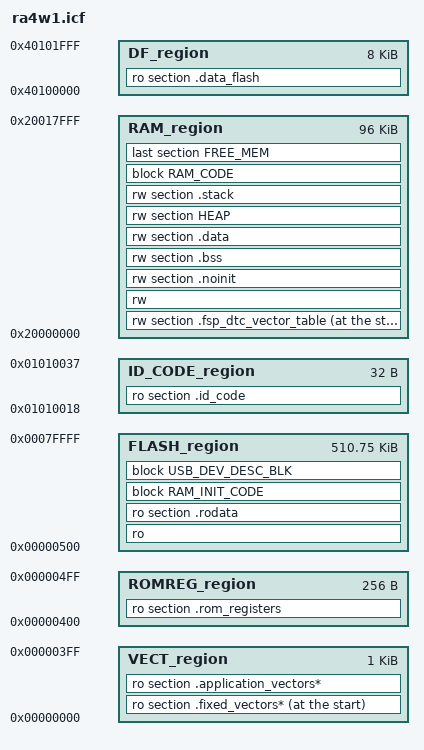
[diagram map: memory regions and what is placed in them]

/*-Memory Regions-*/
define symbol region_VECT_start    = 0x00000000;
define symbol region_VECT_end      = 0x000003FF;
define symbol region_ROMREG_start  = 0x00000400;
define symbol region_ROMREG_end    = 0x000004FF;
define symbol region_FLASH_start   = 0x00000500;
define symbol region_FLASH_end     = 0x0007FFFF;
define symbol region_RAM_start     = 0x20000000;
define symbol region_RAM_end       = 0x20017FFF;
define symbol region_DF_start      = 0x40100000;
define symbol region_DF_end        = 0x40101FFF;

define symbol region_ID_CODES_start    = 0x01010018;
define symbol region_ID_CODES_end      = 0x01010037;

/* Stack and heap sizes are defined in bsp_cfg.h */

define memory mem with size     = 4G;
define region VECT_region       = mem:[from region_VECT_start   to region_VECT_end];
define region ROMREG_region     = mem:[from region_ROMREG_start to region_ROMREG_end];
define region FLASH_region      = mem:[from region_FLASH_start  to region_FLASH_end];
define region RAM_region        = mem:[from region_RAM_start    to region_RAM_end];
define region DF_region         = mem:[from region_DF_start     to region_DF_end];

define region ID_CODE_region    = mem:[from region_ID_CODES_start   to region_ID_CODES_end];

initialize manually { readwrite };
do not initialize   { zeroinit };
initialize manually { section .code_in_ram };
/* Main thread local storage */
initialize manually { section __DLIB_PERTHREAD };

define block RAM_INIT_CODE   { section .code_in_ram_init };
define block RAM_CODE        { section .code_in_ram };
keep                         { section .vector*};

define block USB_DEV_DESC_BLK with fixed order, alignment = 1
                                           { ro data section .usb_device_desc_fs,
                                             ro data section .usb_config_desc_fs,
                                             ro data section .usb_interface_desc_fs,
                                             ro data section .usb_device_desc_hs,
                                             ro data section .usb_config_desc_hs,
                                             ro data section .usb_interface_desc_hs };
keep                                       { section .usb_*};

place at start of VECT_region  { ro section .fixed_vectors* };
place in VECT_region           { ro section .application_vectors* };
place in ROMREG_region         { ro section .rom_registers };
place in FLASH_region   { ro,
                          ro section .rodata,
                          block RAM_INIT_CODE,
                          block USB_DEV_DESC_BLK };
/* If DTC is used, put the DTC vector table at the start of SRAM.
This avoids memory holes due to 1K alignment required by it. */
place at start of RAM_region   { rw section .fsp_dtc_vector_table };

place in ID_CODE_region  { ro section .id_code };

place in RAM_region     { rw,
                          rw section .noinit,
                          rw section .bss,
                          rw section .data,
                          rw section HEAP,
                          rw section .stack,
                          block RAM_CODE };
place in DF_region      { ro section .data_flash };
place in RAM_region     { last section FREE_MEM};

define exported symbol __Vector_Info_Start = region_FLASH_start;
